# earlgrey register map
Vendor: lowRISC; File version: 0.1
CPU: ibex rev01, little endian, no MPU, no FPU, VTOR, 2 interrupt priority bits, 2 interrupts
Registers are 32-bit, read-write, no defined reset value unless marked. A register's access mark holds for its fields unless they carry their own. Offsets are from the block's base; [hi:lo] are bit positions; <NAME> marks a mode.

## GPIO — General-purpose I/O pin control interface for software
Base 0x40040000
0x40 DATA_IN ro — GPIO Input data read value
  [31:0] Value
0x44 DIRECT_OUT — GPIO direct output data write value
  [31:0] Value
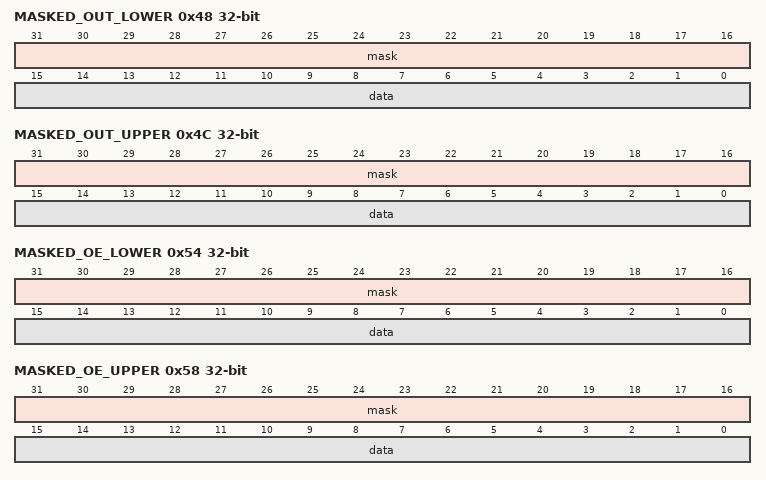
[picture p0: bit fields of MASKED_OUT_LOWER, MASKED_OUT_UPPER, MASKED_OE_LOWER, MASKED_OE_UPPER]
0x48 MASKED_OUT_LOWER — GPIO write data lower with mask.Masked write for DATA_OUT[15:0].Upper 16 bits of this register are used as mask. Writinglower 16 bits of the register changes DATA_OUT[15:0] valueif mask bits are set.Read-back of this register returns upper 16 bits as zeroand lower 16 bits as DATA_OUT[15:0].
  [31:16] mask — Write data mask[15:0].A value of 1 in mask[i] allows the updating of DATA_OUT[i], 0 <= i <= 15
  [15:0] data — Write data value[15:0].Value to write into DATA_OUT[i], valid in the presence of mask[i]==1
0x4C MASKED_OUT_UPPER — GPIO write data upper with mask.Masked write for DATA_OUT[31:16].Upper 16 bits of this register are used as mask. Writinglower 16 bits of the register changes DATA_OUT[31:16] valueif mask bits are set.Read-back of this register returns upper 16 bits as zeroand lower 16 bits as DATA_OUT[31:16].
  [31:16] mask — Write data mask[31:16].A value of 1 in mask[i] allows the updating of DATA_OUT[i], 16 <= i <= 31
  [15:0] data — Write data value[31:16]. Value to write into DATA_OUT[i], valid in the presence of mask[i]==1
0x50 DIRECT_OE — GPIO Output Enable.Setting direct_oe[i] to 1 enables output mode for GPIO[i]
  [31:0] Value
0x54 MASKED_OE_LOWER — GPIO write Output Enable lower with mask.Masked write for DATA_OE[15:0], the register that controlsoutput mode for GPIO pins [15:0].Upper 16 bits of this register are used as mask. Writinglower 16 bits of the register changes DATA_OE[15:0] valueif mask bits are set.Read-back of this register returns upper 16 bits as zeroand lower 16 bits as DATA_OE[15:0].
  [31:16] mask — Write OE mask[15:0].A value of 1 in mask[i] allows the updating of DATA_OE[i], 0 <= i <= 15
  [15:0] data — Write OE value[15:0].Value to write into DATA_OE[i], valid in the presence of mask[i]==1
0x58 MASKED_OE_UPPER — GPIO write Output Enable upper with mask.Masked write for DATA_OE[31:16], the register that controlsoutput mode for GPIO pins [31:16].Upper 16 bits of this register are used as mask. Writinglower 16 bits of the register changes DATA_OE[31:16] valueif mask bits are set.Read-back of this register returns upper 16 bits as zeroand lower 16 bits as DATA_OE[31:16].
  [31:16] mask — Write OE mask[31:16].A value of 1 in mask[i] allows the updating of DATA_OE[i], 16 <= i <= 31
  [15:0] data — Write OE value[31:16].Value to write into DATA_OE[i], valid in the presence of mask[i]==1
0x5C INTR_CTRL_EN_RISING — GPIO interrupt enable for GPIO, rising edge.If !!INTR_ENABLE[i] is true, a value of 1 on !!INTR_CTRL_EN_RISING[i]enables rising-edge interrupt detection on GPIO[i].
  [31:0] Value
0x60 INTR_CTRL_EN_FALLING — GPIO interrupt enable for GPIO, falling edge.If !!INTR_ENABLE[i] is true, a value of 1 on !!INTR_CTRL_EN_FALLING[i]enables falling-edge interrupt detection on GPIO[i].
  [31:0] Value
0x64 INTR_CTRL_EN_LVLHIGH — GPIO interrupt enable for GPIO, level high.If !!INTR_ENABLE[i] is true, a value of 1 on !!INTR_CTRL_EN_LVLHIGH[i]enables level high interrupt detection on GPIO[i].
  [31:0] Value
0x68 INTR_CTRL_EN_LVLLOW — GPIO interrupt enable for GPIO, level low.If !!INTR_ENABLE[i] is true, a value of 1 on !!INTR_CTRL_EN_LVLLOW[i]enables level low interrupt detection on GPIO[i].
  [31:0] Value
0x6C CTRL_EN_INPUT_FILTER — filter enable for GPIO input bits.If !!CTRL_EN_INPUT_FILTER[i] is true, a value of input bit [i]must be stable for 16 cycles before transitioning.
  [31:0] Value
